# ESP32S31_RADIO register map
Vendor: Espressif; Series: ESP32-S31; File version: 3.52
Registers are 32-bit, read-write, no defined reset value unless marked. A register's access mark holds for its fields unless they carry their own. Offsets are from the block's base; [hi:lo] are bit positions.

## EFUSE — eFuse controller read words of block 1: the factory MAC, its extension and the chip and block revisions. The controller mirrors the eFuses into them after reset; reading needs no command.
Base 0x20715000
0x50 RD_MAC_SYS0 ro reset 0x0 — Factory MAC address, low 32 bits.
  [31:0] MAC_0 — MAC address bits 31:0; the last transmitted octet is bits 7:0.
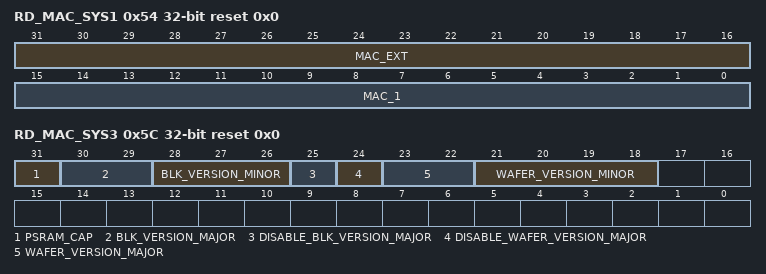
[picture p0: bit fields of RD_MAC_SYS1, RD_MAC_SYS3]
0x54 RD_MAC_SYS1 ro reset 0x0 — Factory MAC address, high 16 bits, and its extended bits.
  [31:16] MAC_EXT — Extended bits of the MAC address.
  [15:0] MAC_1 — MAC address bits 47:32; the first transmitted octet is bits 15:8.
0x5C RD_MAC_SYS3 ro reset 0x0 — Chip and eFuse block revisions and the PSRAM capacity.
  [31] PSRAM_CAP — PSRAM capacity.
  [30:29] BLK_VERSION_MAJOR — Major revision of eFuse block 2.
  [28:26] BLK_VERSION_MINOR — Minor revision of eFuse block 2.
  [25] DISABLE_BLK_VERSION_MAJOR — Disables the check of the major block revision.
  [24] DISABLE_WAFER_VERSION_MAJOR — Disables the check of the major chip revision.
  [23:22] WAFER_VERSION_MAJOR — Major chip revision.
  [21:18] WAFER_VERSION_MINOR — Minor chip revision.

## TRNG — True random number generator: the configuration and health-test words its owner observes, the health-error flag and the conditioned random output.
Base 0x20814000
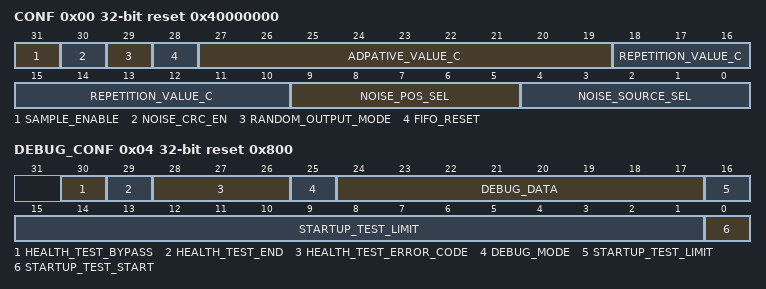
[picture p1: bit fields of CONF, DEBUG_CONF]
0x00 CONF reset 0x40000000 — Noise source, health-test cutoffs and output configuration.
  [31] SAMPLE_ENABLE — Enables noise sampling.
  [30] NOISE_CRC_EN — Enables the CRC conditioner of the noise samples.
  [29] RANDOM_OUTPUT_MODE — Output mode of the random data.
  [28] FIFO_RESET wo — Writing one resets the output FIFO; reads zero.
  [27:19] ADPATIVE_VALUE_C — Cutoff of the adaptive-proportion health test.
  [18:10] REPETITION_VALUE_C — Cutoff of the repetition-count health test.
  [9:5] NOISE_POS_SEL — Sampling-enable selection of the noise source.
  [4:0] NOISE_SOURCE_SEL — Noise source selection, one-hot; zero selects none.
0x04 DEBUG_CONF reset 0x800 — Startup and continuous health-test control and result.
  [30] HEALTH_TEST_BYPASS — Bypasses the health tests.
  [29] HEALTH_TEST_END wo — Writing one ends the health test; reads zero.
  [28:26] HEALTH_TEST_ERROR_CODE ro — Error code of the last failed health test.
  [25] DEBUG_MODE — Debug mode enable.
  [24:17] DEBUG_DATA ro — Debug output data.
  [16:1] STARTUP_TEST_LIMIT — Number of samples the startup health test takes.
  [0] STARTUP_TEST_START wo — Writing one starts the startup health test; reads zero.
0x2C INT_RAW reset 0x0 write-1-clears — Raw health-error interrupt status.
  [0] ERROR_INT_RAW — Set by hardware when a startup or continuous health test fails; writing one clears it.
0x48 CRC_SYNC_DATA ro reset 0x0 — Conditioned random output, synchronized to the bus clock.
  [31:0] SW_CRC_RANDOM_DATA_SYNC — One 32-bit random word.

## LP_PERICLKRST_RNG — Low-power peripheral clock/reset registers: the clock and reset of the true random number generator.
Base 0x20710000
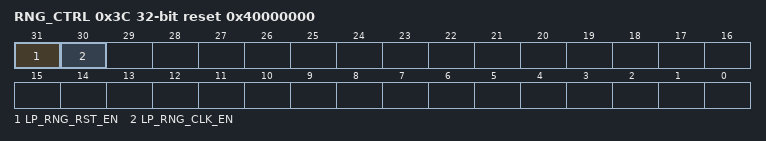
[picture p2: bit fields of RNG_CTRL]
0x3C RNG_CTRL reset 0x40000000 — Random number generator clock and reset control.
  [31] LP_RNG_RST_EN — Random number generator reset; the generator runs only while it is clear.
  [30] LP_RNG_CLK_EN — Random number generator clock enable; set after reset.

## LP_AON_RESET_CAUSE — Low-power always-on clock/reset registers: the reset cause of each HP core. Firmware reads them after boot; the host reads HP core 0's through JTAG after a power cycle.
Base 0x20701000
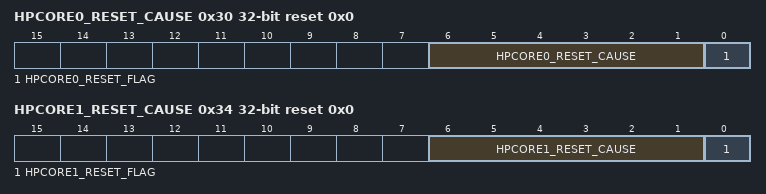
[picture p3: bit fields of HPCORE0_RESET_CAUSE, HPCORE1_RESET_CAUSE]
0x30 HPCORE0_RESET_CAUSE ro reset 0x0 — Why HP core 0 last left reset. It holds until the next reset, so a host reads it through JTAG after the core returned; the ROM reads bits 6:1 of this word for core 0.
  [6:1] HPCORE0_RESET_CAUSE — The reset cause code: one is a power-on reset; others are system, watchdog, brown-out, USB Serial/JTAG and JTAG resets.
  [0] HPCORE0_RESET_FLAG — Set when HP core 0 left reset.
0x34 HPCORE1_RESET_CAUSE ro reset 0x0 — Why HP core 1 last left reset. It holds until the next reset; the ROM reads bits 6:1 of this word for any core but core 0.
  [6:1] HPCORE1_RESET_CAUSE — The reset cause code, with the codes of HP core 0's cause field.
  [0] HPCORE1_RESET_FLAG — Set when HP core 1 left reset.
